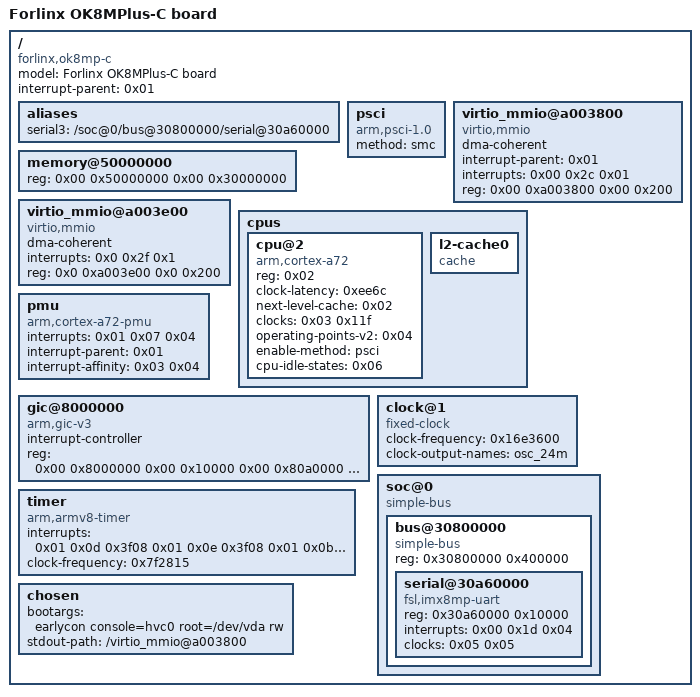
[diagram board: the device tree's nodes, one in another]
/dts-v1/;

/ {
	compatible = "forlinx,ok8mp-c\0fsl,imx8mp-evk\0fsl,imx8mp";
	model = "Forlinx OK8MPlus-C board";
	interrupt-parent = <0x01>;
	#address-cells = <0x02>;
	#size-cells = <0x02>;

	aliases {
		serial3 = "/soc@0/bus@30800000/serial@30a60000";
	};

	psci {
		compatible = "arm,psci-1.0";
		method = "smc";
	};

	memory@50000000 {
		device_type = "memory";
		reg = <0x00 0x50000000 0x00 0x30000000>;
	};

	virtio_mmio@a003800 {
		dma-coherent;
		interrupt-parent = <0x01>;
		interrupts = <0x00 0x2c 0x01>;
		reg = <0x00 0xa003800 0x00 0x200>;
		compatible = "virtio,mmio";
	};

	// virtio disk-first
	virtio_mmio@a003e00 {
	 	dma-coherent;
	 	interrupts = <0x0 0x2f 0x1>;
	 	reg = <0x0 0xa003e00 0x0 0x200>;
	 	compatible = "virtio,mmio";
	};

	cpus {
		#address-cells = <0x01>;
		#size-cells = <0x00>;

		cpu@2 {
			device_type = "cpu";
			compatible = "arm,cortex-a72";
			reg = <0x02>;
			clock-latency = <0xee6c>;
			next-level-cache = <0x02>;
			clocks = <0x03 0x11f>;
			operating-points-v2 = <0x04>;
			enable-method = "psci";
			#cooling-cells = <0x02>;
			cpu-idle-states = <0x06>;
			phandle = <0x13>;
		};

		l2-cache0 {
			compatible = "cache";
			phandle = <0x02>;
		};
	};

	pmu {
		compatible = "arm,cortex-a72-pmu";
		interrupts = <0x01 0x07 0x04>;
		interrupt-parent = <0x01>;
		interrupt-affinity = <0x03 0x04>;
	};

	gic@8000000 {
		compatible = "arm,gic-v3";
		#interrupt-cells = <0x03>;
		interrupt-controller;
		reg = <0x00 0x8000000 0x00 0x10000 0x00 0x80a0000 0x00 0xf60000>;
		phandle = <0x01>;
	};

	timer {
		compatible = "arm,armv8-timer";
		interrupts = <0x01 0x0d 0x3f08 0x01 0x0e 0x3f08 0x01 0x0b 0x3f08 0x01 0x0a 0x3f08>;
		clock-frequency = <0x7f2815>;
	};

	clock@1 {
		compatible = "fixed-clock";
		#clock-cells = <0x00>;
		clock-frequency = <0x16e3600>;
		clock-output-names = "osc_24m";
		phandle = <0x05>;
	};

	soc@0 {
		compatible = "simple-bus";
		#address-cells = <0x01>;
		#size-cells = <0x01>;
		ranges = <0x00 0x00 0x00 0x3e000000>;

		bus@30800000 {
			compatible = "simple-bus";
			#address-cells = <0x01>;
			#size-cells = <0x01>;
			reg = <0x30800000 0x400000>;
			ranges;

			serial@30a60000 {
				compatible = "fsl,imx8mp-uart\0fsl,imx6q-uart";
				reg = <0x30a60000 0x10000>;
				interrupts = <0x00 0x1d 0x04>;
				clocks = <0x05 0x05>;
				clock-names = "ipg\0per";
				status = "okay";
			};
		};
	};

	chosen {
		bootargs = "earlycon console=hvc0 root=/dev/vda rw";
		stdout-path = "/virtio_mmio@a003800";
	};
};
